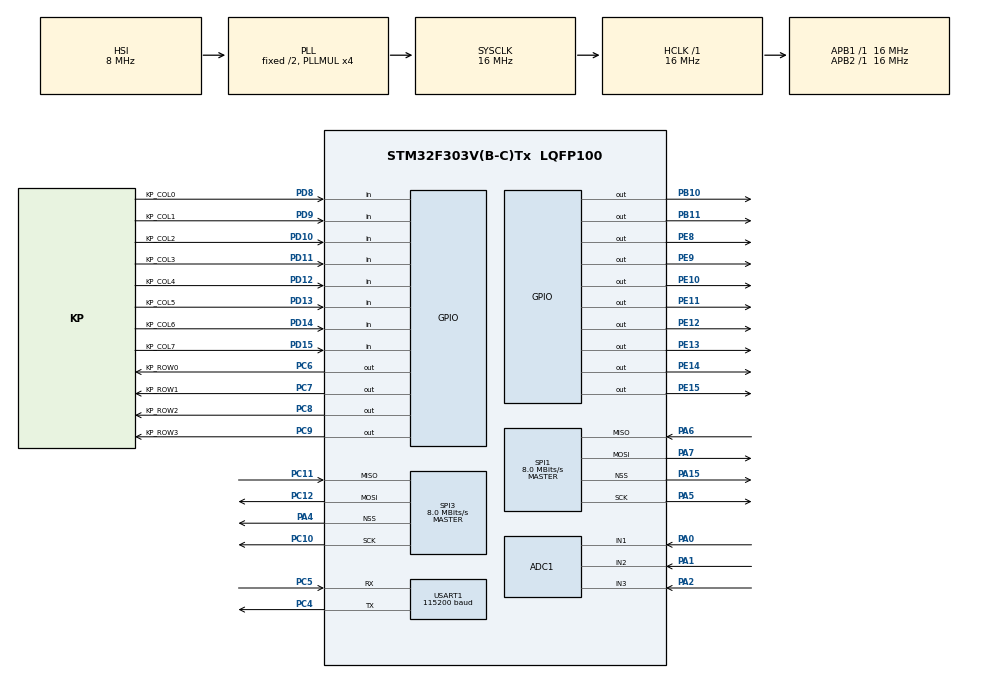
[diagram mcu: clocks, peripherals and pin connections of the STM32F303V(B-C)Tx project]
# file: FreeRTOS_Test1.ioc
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ADC1.Channel-0\#ChannelRegularConversion=ADC_CHANNEL_1
ADC1.ClockPrescaler=ADC_CLOCK_SYNC_PCLK_DIV4
ADC1.NbrOfConversionFlag=1
ADC1.Offset-0\#ChannelRegularConversion=0
ADC1.OffsetNumber-0\#ChannelRegularConversion=ADC_OFFSET_NONE
ADC1.Rank-0\#ChannelRegularConversion=1
ADC1.SamplingTime-0\#ChannelRegularConversion=ADC_SAMPLETIME_1CYCLE_5
ADC1.master=1
FREERTOS.Tasks01=defaultTask,0,128,StartDefaultTask,Default,NULL,Dynamic,NULL,NULL;CmdProcesor,0,128,CmdProcessorTask,Default,NULL,Dynamic,NULL,NULL;Blinky,-3,128,BlinkyTask,Default,NULL,Dynamic,NULL,NULL
FREERTOS.configTOTAL_HEAP_SIZE=4096
FREERTOS.configUSE_TIMERS=1
Mcu.Family=STM32F3
Mcu.Name=STM32F303V(B-C)Tx
Mcu.Package=LQFP100
NVIC.PriorityGroup=NVIC_PRIORITYGROUP_4
NVIC.TIM2_IRQn=true\:0\:0\:false\:false\:true\:false\:false
NVIC.TimeBase=TIM2_IRQn
NVIC.TimeBaseIP=TIM2
NVIC.USART1_IRQn=true\:5\:0\:false\:false\:true\:true\:true
PA0.Mode=IN1-Single-Ended
PA0.Signal=ADC1_IN1
PA1.Mode=IN2-Single-Ended
PA1.Signal=ADC1_IN2
PA13.Mode=Serial_Wire
PA13.Signal=SYS_JTMS-SWDIO
PA14.Mode=Serial_Wire
PA14.Signal=SYS_JTCK-SWCLK
PA15.Mode=NSS_Signal_Hard_Output
PA15.Signal=SPI1_NSS
PA2.Mode=IN3-Single-Ended
PA2.Signal=ADC1_IN3
PA4.Mode=NSS_Signal_Hard_Output
PA4.Signal=SPI3_NSS
PA5.Mode=Full_Duplex_Master
PA5.Signal=SPI1_SCK
PA6.Mode=Full_Duplex_Master
PA6.Signal=SPI1_MISO
PA7.Mode=Full_Duplex_Master
PA7.Signal=SPI1_MOSI
PB10.Signal=GPIO_Output
PB11.Signal=GPIO_Output
PC10.Mode=Full_Duplex_Master
PC10.Signal=SPI3_SCK
PC11.Mode=Full_Duplex_Master
PC11.Signal=SPI3_MISO
PC12.Mode=Full_Duplex_Master
PC12.Signal=SPI3_MOSI
PC4.Mode=Asynchronous
PC4.Signal=USART1_TX
PC5.Mode=Asynchronous
PC5.Signal=USART1_RX
PC6.GPIO_Label=KP_ROW0
PC6.Signal=GPIO_Output
PC7.GPIO_Label=KP_ROW1
PC7.Signal=GPIO_Output
PC8.GPIO_Label=KP_ROW2
PC8.Signal=GPIO_Output
PC9.GPIO_Label=KP_ROW3
PC9.Signal=GPIO_Output
PD10.GPIO_Label=KP_COL2
PD10.Signal=GPIO_Input
PD11.GPIO_Label=KP_COL3
PD11.Signal=GPIO_Input
PD12.GPIO_Label=KP_COL4
PD12.Signal=GPIO_Input
PD13.GPIO_Label=KP_COL5
PD13.Signal=GPIO_Input
PD14.GPIO_Label=KP_COL6
PD14.Signal=GPIO_Input
PD15.GPIO_Label=KP_COL7
PD15.Signal=GPIO_Input
PD8.GPIO_Label=KP_COL0
PD8.Signal=GPIO_Input
PD9.GPIO_Label=KP_COL1
PD9.Signal=GPIO_Input
PE10.Signal=GPIO_Output
PE11.Signal=GPIO_Output
PE12.Signal=GPIO_Output
PE13.Signal=GPIO_Output
PE14.Signal=GPIO_Output
PE15.Signal=GPIO_Output
PE8.Signal=GPIO_Output
PE9.Signal=GPIO_Output
ProjectManager.HeapSize=0x200
ProjectManager.StackSize=0x400
ProjectManager.TargetToolchain=SW4STM32
RCC.AHBFreq_Value=16000000
RCC.APB1Freq_Value=16000000
RCC.APB1TimFreq_Value=16000000
RCC.APB2Freq_Value=16000000
RCC.APB2TimFreq_Value=16000000
RCC.CortexFreq_Value=16000000
RCC.HCLKFreq_Value=16000000
RCC.HSE_VALUE=8000000
RCC.HSI_VALUE=8000000
RCC.LSE_VALUE=32768
RCC.PLLMUL=RCC_PLL_MUL4
RCC.SYSCLKFreq_VALUE=16000000
RCC.SYSCLKSourceVirtual=RCC_SYSCLKSOURCE_PLLCLK
RCC.USBFreq_Value=16000000
SPI1.CalculateBaudRate=8.0 MBits/s
SPI1.DataSize=SPI_DATASIZE_16BIT
SPI1.Direction=SPI_DIRECTION_2LINES
SPI1.Mode=SPI_MODE_MASTER
SPI1.VirtualNSS=VM_NSSHARD
SPI1.VirtualType=VM_MASTER
SPI3.CalculateBaudRate=8.0 MBits/s
SPI3.DataSize=SPI_DATASIZE_16BIT
SPI3.Direction=SPI_DIRECTION_2LINES
SPI3.Mode=SPI_MODE_MASTER
SPI3.VirtualNSS=VM_NSSHARD
SPI3.VirtualType=VM_MASTER
USART1.BaudRate=115200
USART1.VirtualMode-Asynchronous=VM_ASYNC
VP_FREERTOS_VS_ENABLE.Mode=Enabled
VP_SYS_VS_tim2.Mode=TIM2
board=custom

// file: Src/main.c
/**
  ******************************************************************************
  * @file           : main.c
  * @brief          : Main program body
  ******************************************************************************
  * This notice applies to any and all portions of this file
  * that are not between comment pairs USER CODE BEGIN and
  * USER CODE END. Other portions of this file, whether
  * inserted by the user or by software development tools
  * are owned by their respective copyright owners.
  *
  * Copyright (c) 2018 STMicroelectronics International N.V.
  * All rights reserved.
  *
  * Redistribution and use in source and binary forms, with or without
  * modification, are permitted, provided that the following conditions are met:
  *
  * 1. Redistribution of source code must retain the above copyright notice,
  *    this list of conditions and the following disclaimer.
  * 2. Redistributions in binary form must reproduce the above copyright notice,
  *    this list of conditions and the following disclaimer in the documentation
  *    and/or other materials provided with the distribution.
  * 3. Neither the name of STMicroelectronics nor the names of other
  *    contributors to this software may be used to endorse or promote products
  *    derived from this software without specific written permission.
  * 4. This software, including modifications and/or derivative works of this
  *    software, must execute solely and exclusively on microcontroller or
  *    microprocessor devices manufactured by or for STMicroelectronics.
  * 5. Redistribution and use of this software other than as permitted under
  *    this license is void and will automatically terminate your rights under
  *    this license.
  *
  * THIS SOFTWARE IS PROVIDED BY STMICROELECTRONICS AND CONTRIBUTORS "AS IS"
  * AND ANY EXPRESS, IMPLIED OR STATUTORY WARRANTIES, INCLUDING, BUT NOT
  * LIMITED TO, THE IMPLIED WARRANTIES OF MERCHANTABILITY, FITNESS FOR A
  * PARTICULAR PURPOSE AND NON-INFRINGEMENT OF THIRD PARTY INTELLECTUAL PROPERTY
  * RIGHTS ARE DISCLAIMED TO THE FULLEST EXTENT PERMITTED BY LAW. IN NO EVENT
  * SHALL STMICROELECTRONICS OR CONTRIBUTORS BE LIABLE FOR ANY DIRECT, INDIRECT,
  * INCIDENTAL, SPECIAL, EXEMPLARY, OR CONSEQUENTIAL DAMAGES (INCLUDING, BUT NOT
  * LIMITED TO, PROCUREMENT OF SUBSTITUTE GOODS OR SERVICES; LOSS OF USE, DATA,
  * OR PROFITS; OR BUSINESS INTERRUPTION) HOWEVER CAUSED AND ON ANY THEORY OF
  * LIABILITY, WHETHER IN CONTRACT, STRICT LIABILITY, OR TORT (INCLUDING
  * NEGLIGENCE OR OTHERWISE) ARISING IN ANY WAY OUT OF THE USE OF THIS SOFTWARE,
  * EVEN IF ADVISED OF THE POSSIBILITY OF SUCH DAMAGE.
  *
  ******************************************************************************
  */
#include "main.h"
#include "stm32f3xx_hal.h"
#include "cmsis_os.h"
#include "adc.h"
#include "spi.h"
#include "usart.h"
#include "gpio.h"
#include "ringbuffer.h"

/* USER CODE BEGIN PV */
/* Private variables ---------------------------------------------------------*/
ringbuf_uint8t uart_rx_rb;
uint8_t uart_tmp_rx_char;
#define uart_rx_buffer_size 128
uint8_t uart_rx_buffer[uart_rx_buffer_size];

/* USER CODE END PV */

void SystemClock_Config(void);
void MX_FREERTOS_Init(void);

/* USER CODE BEGIN PFP */
/* Private function prototypes -----------------------------------------------*/

/* USER CODE END PFP */

int main(void)
{

  /* MCU Configuration----------------------------------------------------------*/

  /* Reset of all peripherals, Initializes the Flash interface and the Systick. */
  HAL_Init();

  /* Configure the system clock */
  SystemClock_Config();

  /* Initialize all configured peripherals */
  MX_GPIO_Init();
  MX_USART1_UART_Init();
  MX_SPI1_Init();
  MX_SPI3_Init();
  MX_ADC1_Init();
  /* USER CODE BEGIN 2 */

  // initialize uart receive data ringbuffer
  rb_init(&uart_rx_rb, uart_rx_buffer, uart_rx_buffer_size);
  // start chain of interrupts to receive data.
  HAL_UART_Receive_IT(&huart1, &uart_tmp_rx_char, 1 );

  /* USER CODE END 2 */

  /* Call init function for freertos objects (in freertos.c) */
  MX_FREERTOS_Init();

  /* Start scheduler */
  osKernelStart();

  /* We should never get here as control is now taken by the scheduler */

  /* Infinite loop */
  /* USER CODE BEGIN WHILE */
  while (1)
  {
	  HAL_GPIO_TogglePin(GPIOE, GPIO_PIN_11 );
  }
  /* USER CODE END 3 */

}

void SystemClock_Config(void)
{

  RCC_OscInitTypeDef RCC_OscInitStruct;
  RCC_ClkInitTypeDef RCC_ClkInitStruct;
  RCC_PeriphCLKInitTypeDef PeriphClkInit;

    /**Initializes the CPU, AHB and APB busses clocks
    */
  RCC_OscInitStruct.OscillatorType = RCC_OSCILLATORTYPE_HSI;
  RCC_OscInitStruct.HSIState = RCC_HSI_ON;
  RCC_OscInitStruct.HSICalibrationValue = 16;
  RCC_OscInitStruct.PLL.PLLState = RCC_PLL_ON;
  RCC_OscInitStruct.PLL.PLLSource = RCC_PLLSOURCE_HSI;
  RCC_OscInitStruct.PLL.PLLMUL = RCC_PLL_MUL4;
  if (HAL_RCC_OscConfig(&RCC_OscInitStruct) != HAL_OK)
  {
    _Error_Handler(__FILE__, __LINE__);
  }

    /**Initializes the CPU, AHB and APB busses clocks
    */
  RCC_ClkInitStruct.ClockType = RCC_CLOCKTYPE_HCLK|RCC_CLOCKTYPE_SYSCLK
                              |RCC_CLOCKTYPE_PCLK1|RCC_CLOCKTYPE_PCLK2;
  RCC_ClkInitStruct.SYSCLKSource = RCC_SYSCLKSOURCE_PLLCLK;
  RCC_ClkInitStruct.AHBCLKDivider = RCC_SYSCLK_DIV1;
  RCC_ClkInitStruct.APB1CLKDivider = RCC_HCLK_DIV1;
  RCC_ClkInitStruct.APB2CLKDivider = RCC_HCLK_DIV1;

  if (HAL_RCC_ClockConfig(&RCC_ClkInitStruct, FLASH_LATENCY_0) != HAL_OK)
  {
    _Error_Handler(__FILE__, __LINE__);
  }

  PeriphClkInit.PeriphClockSelection = RCC_PERIPHCLK_USART1;
  PeriphClkInit.Usart1ClockSelection = RCC_USART1CLKSOURCE_PCLK2;
  if (HAL_RCCEx_PeriphCLKConfig(&PeriphClkInit) != HAL_OK)
  {
    _Error_Handler(__FILE__, __LINE__);
  }

    /**Configure the Systick interrupt time
    */
  HAL_SYSTICK_Config(HAL_RCC_GetHCLKFreq()/1000);

    /**Configure the Systick
    */
  HAL_SYSTICK_CLKSourceConfig(SYSTICK_CLKSOURCE_HCLK);

  /* SysTick_IRQn interrupt configuration */
  HAL_NVIC_SetPriority(SysTick_IRQn, 15, 0);
}

void HAL_TIM_PeriodElapsedCallback(TIM_HandleTypeDef *htim)
{
  if (htim->Instance == TIM2) {
    HAL_IncTick();
  }
}

void _Error_Handler(char *file, int line)
{
  while(1)
  {
  }
}

// UART receive interrupt callback
void HAL_UART_RxCpltCallback(UART_HandleTypeDef *huart)
{
  /* Prevent unused argument(s) compilation warning */
  // add received char to ring buffer.
  rb_put(&uart_rx_rb, uart_tmp_rx_char );
  // kick off the next read
  HAL_UART_Receive_IT(&huart1, &uart_tmp_rx_char, 1 );
}

/************************ (C) COPYRIGHT STMicroelectronics *****END OF FILE****/

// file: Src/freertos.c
/* USER CODE BEGIN Header */
/**
  ******************************************************************************
  * File Name          : freertos.c
  * Description        : Code for freertos applications
  ******************************************************************************
  * This notice applies to any and all portions of this file
  * that are not between comment pairs USER CODE BEGIN and
  * USER CODE END. Other portions of this file, whether
  * inserted by the user or by software development tools
  * are owned by their respective copyright owners.
  *
  * Copyright (c) 2018 STMicroelectronics International N.V.
  * All rights reserved.
  *
  * Redistribution and use in source and binary forms, with or without
  * modification, are permitted, provided that the following conditions are met:
  *
  * 1. Redistribution of source code must retain the above copyright notice,
  *    this list of conditions and the following disclaimer.
  * 2. Redistributions in binary form must reproduce the above copyright notice,
  *    this list of conditions and the following disclaimer in the documentation
  *    and/or other materials provided with the distribution.
  * 3. Neither the name of STMicroelectronics nor the names of other
  *    contributors to this software may be used to endorse or promote products
  *    derived from this software without specific written permission.
  * 4. This software, including modifications and/or derivative works of this
  *    software, must execute solely and exclusively on microcontroller or
  *    microprocessor devices manufactured by or for STMicroelectronics.
  * 5. Redistribution and use of this software other than as permitted under
  *    this license is void and will automatically terminate your rights under
  *    this license.
  *
  * THIS SOFTWARE IS PROVIDED BY STMICROELECTRONICS AND CONTRIBUTORS "AS IS"
  * AND ANY EXPRESS, IMPLIED OR STATUTORY WARRANTIES, INCLUDING, BUT NOT
  * LIMITED TO, THE IMPLIED WARRANTIES OF MERCHANTABILITY, FITNESS FOR A
  * PARTICULAR PURPOSE AND NON-INFRINGEMENT OF THIRD PARTY INTELLECTUAL PROPERTY
  * RIGHTS ARE DISCLAIMED TO THE FULLEST EXTENT PERMITTED BY LAW. IN NO EVENT
  * SHALL STMICROELECTRONICS OR CONTRIBUTORS BE LIABLE FOR ANY DIRECT, INDIRECT,
  * INCIDENTAL, SPECIAL, EXEMPLARY, OR CONSEQUENTIAL DAMAGES (INCLUDING, BUT NOT
  * LIMITED TO, PROCUREMENT OF SUBSTITUTE GOODS OR SERVICES; LOSS OF USE, DATA,
  * OR PROFITS; OR BUSINESS INTERRUPTION) HOWEVER CAUSED AND ON ANY THEORY OF
  * LIABILITY, WHETHER IN CONTRACT, STRICT LIABILITY, OR TORT (INCLUDING
  * NEGLIGENCE OR OTHERWISE) ARISING IN ANY WAY OUT OF THE USE OF THIS SOFTWARE,
  * EVEN IF ADVISED OF THE POSSIBILITY OF SUCH DAMAGE.
  *
  ******************************************************************************
  */
/* USER CODE END Header */

#include "FreeRTOS.h"
#include "task.h"
#include "main.h"
#include "cmsis_os.h"
#include "gpio.h"
#include "usart.h"
#include "ringbuffer.h"

// ring buffer of received chars from the UART.
extern ringbuf_uint8t uart_rx_rb;

osThreadId defaultTaskHandle;
osThreadId CmdProcesorHandle;
osThreadId BlinkyHandle;

void StartDefaultTask(void const * argument);
void CmdProcessorTask(void const * argument);
void BlinkyTask(void const * argument);
void MX_FREERTOS_Init(void); /* (MISRA C 2004 rule 8.1) */

void MX_FREERTOS_Init(void) {

  /* Create the thread(s) */
  /* definition and creation of defaultTask */
  osThreadDef(defaultTask, StartDefaultTask, osPriorityNormal, 0, 128);
  defaultTaskHandle = osThreadCreate(osThread(defaultTask), NULL);

  /* definition and creation of CmdProcesor */
  osThreadDef(CmdProcesor, CmdProcessorTask, osPriorityNormal, 0, 128);
  CmdProcesorHandle = osThreadCreate(osThread(CmdProcesor), NULL);

  /* definition and creation of Blinky */
  //osThreadDef(Blinky, BlinkyTask, osPriorityIdle, 0, 128);
  //BlinkyHandle = osThreadCreate(osThread(Blinky), NULL);

}

void StartDefaultTask(void const * argument)
{

  /* USER CODE BEGIN StartDefaultTask */
  /* Infinite loop */
  for(;;)
  {
    osDelay(1000);
    HAL_GPIO_TogglePin(GPIOE, GPIO_PIN_13 );
  }
  /* USER CODE END StartDefaultTask */
}

void CmdProcessorTask(void const * argument)
{
  char startup_message[] = "Starting\x0A\x0D";
  HAL_UART_Transmit(&huart1, (uint8_t*)startup_message, sizeof(startup_message), 1000);

  while(1)
  {
	// echo back chars received in ring buffer.
	if ( !rb_isempty(&uart_rx_rb) ) {
	  // have data to echo back.
	  uint8_t *tx_byte_ptr = rb_get(&uart_rx_rb);
	  // blocking UART TX data call
	  HAL_UART_Transmit(&huart1, tx_byte_ptr, 1, 1000);
	  HAL_GPIO_TogglePin(GPIOE, GPIO_PIN_12 );
    }
  }
}

/*void BlinkyTask(void const * argument)
{
  for(;;)
  {
    osDelay(1000);
	HAL_GPIO_TogglePin(GPIOE, GPIO_PIN_10 );
  }
}*/

/************************ (C) COPYRIGHT STMicroelectronics *****END OF FILE****/
